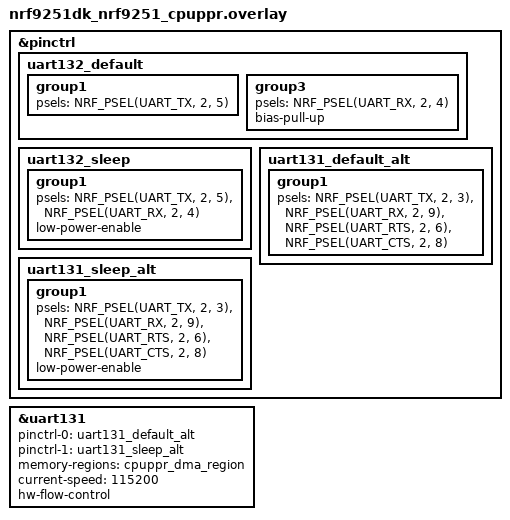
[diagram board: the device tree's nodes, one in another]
/*
 * Copyright (c) 2026 Nordic Semiconductor ASA
 *
 * SPDX-License-Identifier: LicenseRef-Nordic-5-Clause
 */

/* Test requires loopbacks:
 * TX-RX: P2.03 - P2.09
 * RTS-CTS: P2.06 - P2.08
 */

&pinctrl {
	/* Console without RTS/CTS, as P2.06 and P2.08 are used by the test. */
	uart132_default: uart132_default {
		group1 {
			psels = <NRF_PSEL(UART_TX, 2, 5)>;
		};

		group3 {
			psels = <NRF_PSEL(UART_RX, 2, 4)>;
			bias-pull-up;
		};
	};

	uart132_sleep: uart132_sleep {
		group1 {
			psels = <NRF_PSEL(UART_TX, 2, 5)>,
				<NRF_PSEL(UART_RX, 2, 4)>;
			low-power-enable;
		};
	};

	uart131_default_alt: uart131_default_alt {
		group1 {
			psels = <NRF_PSEL(UART_TX, 2, 3)>,
				<NRF_PSEL(UART_RX, 2, 9)>,
				<NRF_PSEL(UART_RTS, 2, 6)>,
				<NRF_PSEL(UART_CTS, 2, 8)>;
		};
	};

	uart131_sleep_alt: uart131_sleep_alt {
		group1 {
			psels = <NRF_PSEL(UART_TX, 2, 3)>,
				<NRF_PSEL(UART_RX, 2, 9)>,
				<NRF_PSEL(UART_RTS, 2, 6)>,
				<NRF_PSEL(UART_CTS, 2, 8)>;
			low-power-enable;
		};
	};
};

dut: &uart131 {
	status = "okay";
	pinctrl-0 = <&uart131_default_alt>;
	pinctrl-1 = <&uart131_sleep_alt>;
	pinctrl-names = "default", "sleep";
	memory-regions = <&cpuppr_dma_region>;
	current-speed = <115200>;
	hw-flow-control;
};
